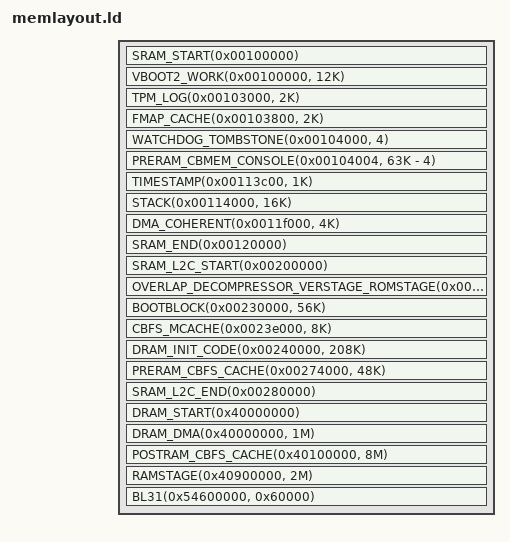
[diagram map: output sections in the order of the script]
/* SPDX-License-Identifier: GPL-2.0-only */

#include <soc/memlayout.h>

SECTIONS
{
	SRAM_START(0x00100000)
	VBOOT2_WORK(0x00100000, 12K)
	TPM_LOG(0x00103000, 2K)
	FMAP_CACHE(0x00103800, 2K)
	WATCHDOG_TOMBSTONE(0x00104000, 4)
	PRERAM_CBMEM_CONSOLE(0x00104004, 63K - 4)
	TIMESTAMP(0x00113c00, 1K)
	STACK(0x00114000, 16K)
	TTB(0x00118000, 28K)
	DMA_COHERENT(0x0011f000, 4K)
	SRAM_END(0x00120000)

	SRAM_L2C_START(0x00200000)
	OVERLAP_DECOMPRESSOR_VERSTAGE_ROMSTAGE(0x00201000, 188K)
	BOOTBLOCK(0x00230000, 56K)
	CBFS_MCACHE(0x0023e000, 8K)
	DRAM_INIT_CODE(0x00240000, 208K)
	PRERAM_CBFS_CACHE(0x00274000, 48K)
	SRAM_L2C_END(0x00280000)

	DRAM_START(0x40000000)
	DRAM_DMA(0x40000000, 1M)
	POSTRAM_CBFS_CACHE(0x40100000, 8M)
	RAMSTAGE(0x40900000, 2M)

	BL31(0x54600000, 0x60000)
}
